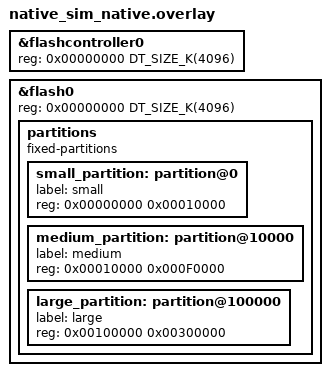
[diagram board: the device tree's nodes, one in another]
/*
 * Copyright (c) 2019 Jan Van Winkel <jan.van_winkel@dxplore.eu>
 *
 * SPDX-License-Identifier: Apache-2.0
 */

&flashcontroller0 {
	reg = <0x00000000 DT_SIZE_K(4096)>;
};

&flash0 {
	reg = <0x00000000 DT_SIZE_K(4096)>;
	partitions {
		compatible = "fixed-partitions";
		#address-cells = <1>;
		#size-cells = <1>;

		small_partition: partition@0 {
			label = "small";
			reg = <0x00000000 0x00010000>;
		};
		medium_partition: partition@10000 {
			label = "medium";
			reg = <0x00010000 0x000F0000>;
		};
		large_partition: partition@100000 {
			label = "large";
			reg = <0x00100000 0x00300000>;
		};
	};
};
